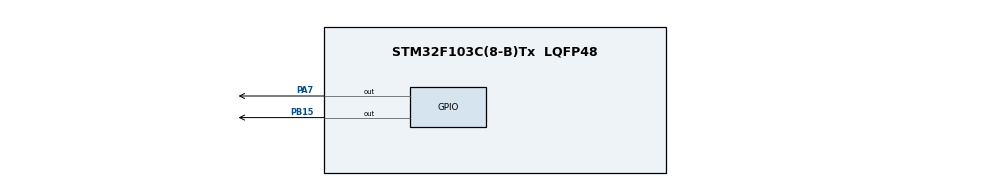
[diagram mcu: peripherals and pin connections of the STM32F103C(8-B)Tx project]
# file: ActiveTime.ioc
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FREERTOS.Tasks01=startBlink1,24,128,blink1,Default,NULL,Dynamic,NULL,NULL;startBlink2,16,128,blink2,Default,NULL,Dynamic,NULL,NULL
Mcu.Family=STM32F1
Mcu.Name=STM32F103C(8-B)Tx
Mcu.Package=LQFP48
NVIC.PriorityGroup=NVIC_PRIORITYGROUP_4
NVIC.TIM4_IRQn=true\:15\:0\:false\:false\:true\:false\:false\:true
NVIC.TimeBase=TIM4_IRQn
NVIC.TimeBaseIP=TIM4
PA7.Signal=GPIO_Output
PB15.Signal=GPIO_Output
ProjectManager.HeapSize=0x200
ProjectManager.StackSize=0x400
ProjectManager.TargetToolchain=MDK-ARM V5.32
RCC.APB1Freq_Value=8000000
RCC.APB2Freq_Value=8000000
VP_FREERTOS_VS_CMSIS_V2.Mode=CMSIS_V2
VP_SYS_VS_ND.Mode=No_Debug
VP_SYS_VS_tim4.Mode=TIM4
board=custom

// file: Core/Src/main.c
/* USER CODE BEGIN Header */
/**
  ******************************************************************************
  * @file           : main.c
  * @brief          : Main program body
  ******************************************************************************
  * @attention
  *
  * Copyright (c) 2022 STMicroelectronics.
  * All rights reserved.
  *
  * This software is licensed under terms that can be found in the LICENSE file
  * in the root directory of this software component.
  * If no LICENSE file comes with this software, it is provided AS-IS.
  *
  ******************************************************************************
  */
/* USER CODE END Header */
#include "main.h"
#include "cmsis_os.h"

	uint32_t signal1;
uint32_t signal2;

/* Definitions for startBlink1 */
osThreadId_t startBlink1Handle;
const osThreadAttr_t startBlink1_attributes = {
  .name = "startBlink1",
  .stack_size = 128 * 4,
  .priority = (osPriority_t) osPriorityNormal,
};
/* Definitions for startBlink2 */
osThreadId_t startBlink2Handle;
const osThreadAttr_t startBlink2_attributes = {
  .name = "startBlink2",
  .stack_size = 128 * 4,
  .priority = (osPriority_t) osPriorityBelowNormal,
};

void SystemClock_Config(void);
static void MX_GPIO_Init(void);
void blink1(void *argument);
void blink2(void *argument);

int main(void)
{

  /* MCU Configuration--------------------------------------------------------*/

  /* Reset of all peripherals, Initializes the Flash interface and the Systick. */
  HAL_Init();

  /* Configure the system clock */
  SystemClock_Config();

  /* Initialize all configured peripherals */
  MX_GPIO_Init();

  /* Init scheduler */
  osKernelInitialize();

  /* Create the thread(s) */
  /* creation of startBlink1 */
  startBlink1Handle = osThreadNew(blink1, NULL, &startBlink1_attributes);

  /* creation of startBlink2 */
  startBlink2Handle = osThreadNew(blink2, NULL, &startBlink2_attributes);

  /* Start scheduler */
  osKernelStart();

  /* We should never get here as control is now taken by the scheduler */
  /* Infinite loop */
  while (1)
  {

  }
}

void SystemClock_Config(void)
{
  RCC_OscInitTypeDef RCC_OscInitStruct = {0};
  RCC_ClkInitTypeDef RCC_ClkInitStruct = {0};

  /** Initializes the RCC Oscillators according to the specified parameters
  * in the RCC_OscInitTypeDef structure.
  */
  RCC_OscInitStruct.OscillatorType = RCC_OSCILLATORTYPE_HSI;
  RCC_OscInitStruct.HSIState = RCC_HSI_ON;
  RCC_OscInitStruct.HSICalibrationValue = RCC_HSICALIBRATION_DEFAULT;
  RCC_OscInitStruct.PLL.PLLState = RCC_PLL_NONE;
  if (HAL_RCC_OscConfig(&RCC_OscInitStruct) != HAL_OK)
  {
    Error_Handler();
  }
  /** Initializes the CPU, AHB and APB buses clocks
  */
  RCC_ClkInitStruct.ClockType = RCC_CLOCKTYPE_HCLK|RCC_CLOCKTYPE_SYSCLK
                              |RCC_CLOCKTYPE_PCLK1|RCC_CLOCKTYPE_PCLK2;
  RCC_ClkInitStruct.SYSCLKSource = RCC_SYSCLKSOURCE_HSI;
  RCC_ClkInitStruct.AHBCLKDivider = RCC_SYSCLK_DIV1;
  RCC_ClkInitStruct.APB1CLKDivider = RCC_HCLK_DIV1;
  RCC_ClkInitStruct.APB2CLKDivider = RCC_HCLK_DIV1;

  if (HAL_RCC_ClockConfig(&RCC_ClkInitStruct, FLASH_LATENCY_0) != HAL_OK)
  {
    Error_Handler();
  }
}

static void MX_GPIO_Init(void)
{
  GPIO_InitTypeDef GPIO_InitStruct = {0};

  /* GPIO Ports Clock Enable */
  __HAL_RCC_GPIOA_CLK_ENABLE();
  __HAL_RCC_GPIOB_CLK_ENABLE();

  /*Configure GPIO pin Output Level */
  HAL_GPIO_WritePin(GPIOA, GPIO_PIN_7, GPIO_PIN_RESET);

  /*Configure GPIO pin Output Level */
  HAL_GPIO_WritePin(GPIOB, GPIO_PIN_15, GPIO_PIN_RESET);

  /*Configure GPIO pin : PA7 */
  GPIO_InitStruct.Pin = GPIO_PIN_7;
  GPIO_InitStruct.Mode = GPIO_MODE_OUTPUT_PP;
  GPIO_InitStruct.Pull = GPIO_NOPULL;
  GPIO_InitStruct.Speed = GPIO_SPEED_FREQ_LOW;
  HAL_GPIO_Init(GPIOA, &GPIO_InitStruct);

  /*Configure GPIO pin : PB15 */
  GPIO_InitStruct.Pin = GPIO_PIN_15;
  GPIO_InitStruct.Mode = GPIO_MODE_OUTPUT_PP;
  GPIO_InitStruct.Pull = GPIO_NOPULL;
  GPIO_InitStruct.Speed = GPIO_SPEED_FREQ_LOW;
  HAL_GPIO_Init(GPIOB, &GPIO_InitStruct);

}

void blink1(void *argument)
{
  /* USER CODE BEGIN 5 */
  /* Infinite loop */
  for(;;)
  {
		signal1=1;
		HAL_GPIO_TogglePin(GPIOA, GPIO_PIN_7);
    osDelay(5000);
		HAL_GPIO_WritePin(GPIOA, GPIO_PIN_7,GPIO_PIN_RESET);
    signal1=0;
		osDelay(20000);

  }
  /* USER CODE END 5 */
}

void blink2(void *argument)
{
  /* USER CODE BEGIN blink2 */
  /* Infinite loop */
  for(;;)
  {
		signal2=1;
		HAL_GPIO_TogglePin(GPIOB, GPIO_PIN_15);
    osDelay(10000);
		HAL_GPIO_WritePin(GPIOB, GPIO_PIN_15,GPIO_PIN_RESET);
		signal2=0;
    osDelay(20000);
  }
  /* USER CODE END blink2 */
}

void HAL_TIM_PeriodElapsedCallback(TIM_HandleTypeDef *htim)
{
  if (htim->Instance == TIM4) {
    HAL_IncTick();
  }
}

void Error_Handler(void)
{
  __disable_irq();
  while (1)
  {
  }
}
